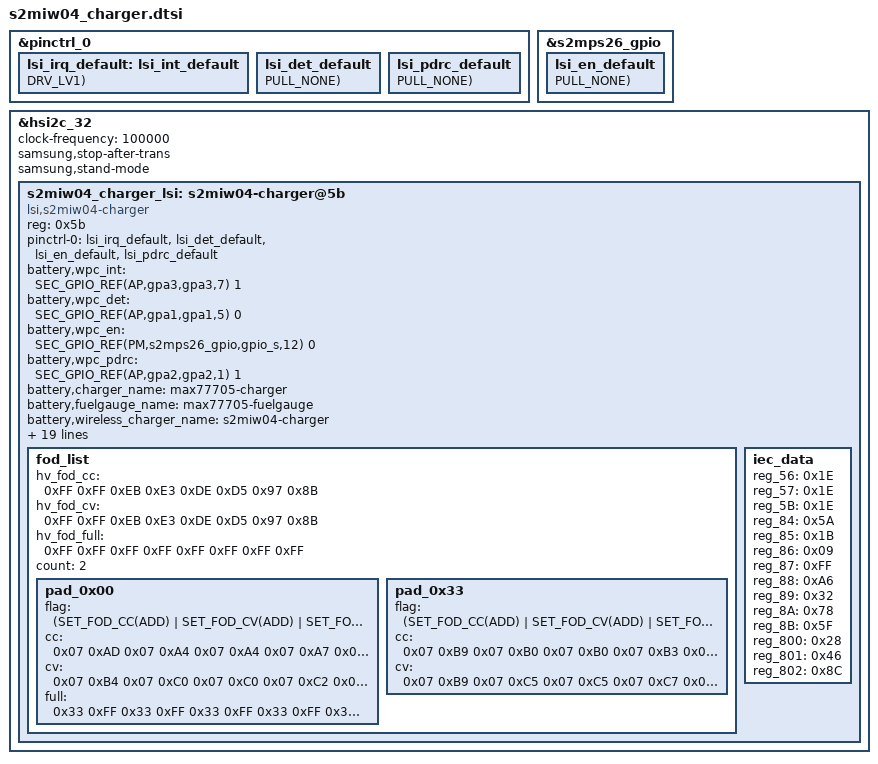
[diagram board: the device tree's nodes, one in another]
#include <dt-bindings/battery/sec-battery.h>

&pinctrl_0 {
	lsi_irq_default: lsi_int_default {
		GPIO_CONFIG_PUD_DRV(AP,gpa3,gpa3,7, FUNC_INPUT_WAKEUP, PULL_NONE, DRV_LV1);
	};
};

&pinctrl_0 {
	lsi_det_default: lsi_det_default {
		GPIO_CONFIG_PUD(AP,gpa1,gpa1,5, FUNC_INPUT_WAKEUP, PULL_NONE);
	};
};

&s2mps26_gpio {
	lsi_en_default: lsi_en_default {
		GPIO_CONFIG_PUD(PM,s2mps26_gpio,gpio_s,12, FUNC_OUTPUT_LOW, PULL_NONE);
	};
};

&hsi2c_32 {
	#address-cells = <1>;
	#size-cells = <0>;
	status = "okay";
	clock-frequency = <100000>;

	s2miw04_charger: s2miw04-charger@3b {
		compatible = "lsi,s2miw04-charger";
		reg = <0x3b>;
		status = "okay";

		pinctrl-names = "default";
		pinctrl-0 = <&lsi_irq_default &lsi_det_default &lsi_en_default>;

		battery,wpc_int = <SEC_GPIO_REF(AP,gpa3,gpa3,7) 1>; /* MFC_AP_INT */
		battery,wpc_det = <SEC_GPIO_REF(AP,gpa1,gpa1,5) 0>; /* WPC_DET */
#if 0
		battery,mst_pwr_en = <SEC_GPIO_REF(${lsi_pwr_en_gpio}) 0>; /* MST_PWR_EN */
#endif
		battery,wpc_en = <SEC_GPIO_REF(PM,s2mps26_gpio,gpio_s,12) 0>; /* WPC_EN */

		battery,charger_name = "max77705-charger";
		battery,fuelgauge_name = "max77705-fuelgauge";
		battery,wireless_charger_name = "s2miw04-charger";
		battery,wc_cover_rpp = <0x44>;
		battery,phone_fod_threshold = <0x3b>;
		battery,wireless20_vout_list = <WIRELESS_VOUT_11V /* 0xA0 */
						WIRELESS_VOUT_11V /* 0xA1 */
						WIRELESS_VOUT_11V /* 0xA2 */
						WIRELESS_VOUT_11V /* 0xA3 */
						WIRELESS_VOUT_11V /* 0xA4 */
						WIRELESS_VOUT_11V>; /* 0xA5 */
		battery,wireless20_vrect_list = <MFC_AFC_CONF_12V_TX
						MFC_AFC_CONF_12_5V_TX
						MFC_AFC_CONF_12_5V_TX
						MFC_AFC_CONF_12_5V_TX
						MFC_AFC_CONF_12_5V_TX
						MFC_AFC_CONF_12_5V_TX>;
		battery,wireless20_max_power_list = <SEC_WIRELESS_RX_POWER_12W
						SEC_WIRELESS_RX_POWER_15W
						SEC_WIRELESS_RX_POWER_15W
						SEC_WIRELESS_RX_POWER_15W
						SEC_WIRELESS_RX_POWER_15W
						SEC_WIRELESS_RX_POWER_15W>;
		battery,oc_fod1 = <1100>;

		fod_list {
			count = <1>;

			pad_0x00 { /* DEFAULT */
				flag = <(SET_FOD_CC(ADD) | SET_FOD_CV(USE_CC) | SET_FOD_FULL(ADD))>;
				cc = <0x06 0xAA 0x06 0xAA 0x06 0xAA 0x06 0x99 0x06 0x99
					0x06 0x99 0x0C 0x85 0x0C 0x85 0x08 0x9E 0x08 0x9E>;
				full = <0xFF 0xFF 0xFF 0xFF 0xFF 0xFF 0xFF 0xFF 0xFF 0xFF
					0xFF 0xFF 0xFF 0xFF 0xFF 0xFF 0xFF 0xFF 0xFF 0xFF>;
			};
		};
	};
};

/* /home/dpi/qb5_8815/workspace/P4_1716/android/kernel/kmodule/battery/stable/r11/wireless/s2miw04/s2miw04_charger.r11s.dtsi */
#include <dt-bindings/battery/sec-battery.h>

#if 1
&pinctrl_0 {
	lsi_pdrc_default: lsi_pdrc_default {
		GPIO_CONFIG_PUD(AP,gpa2,gpa2,1, FUNC_INPUT_WAKEUP, PULL_NONE);
	};
};
#endif

&hsi2c_32 {
	samsung,stop-after-trans;
	samsung,stand-mode;

	/delete-node/ s2miw04-charger@3b;

	s2miw04_charger_lsi: s2miw04-charger@5b {
		compatible = "lsi,s2miw04-charger";
		reg = <0x5b>;
		status = "okay";

		pinctrl-names = "default";
#if 1
		pinctrl-0 = <&lsi_irq_default &lsi_det_default &lsi_en_default &lsi_pdrc_default>;
#else
		pinctrl-0 = <&lsi_irq_default &lsi_det_default &lsi_en_default>;
#endif

		battery,wpc_int = <SEC_GPIO_REF(AP,gpa3,gpa3,7) 1>; /* MFC_AP_INT */
		battery,wpc_det = <SEC_GPIO_REF(AP,gpa1,gpa1,5) 0>; /* WPC_DET */
#if 0
		battery,mst_pwr_en = <SEC_GPIO_REF(${lsi_pwr_en_gpio}) 0>; /* MST_PWR_EN */
#endif
		battery,wpc_en = <SEC_GPIO_REF(PM,s2mps26_gpio,gpio_s,12) 0>; /* WPC_EN */
#if 1
		battery,wpc_pdrc = <SEC_GPIO_REF(AP,gpa2,gpa2,1) 1>; /* VRECT_INT */
#endif

		battery,charger_name = "max77705-charger";
		battery,fuelgauge_name = "max77705-fuelgauge";
		battery,wireless_charger_name = "s2miw04-charger";
		battery,wc_cover_rpp = <0x44>;
		battery,phone_fod_threshold = <0x3b>;
		battery,wireless20_vout_list = <WIRELESS_VOUT_9V /* 0xA0 */
						WIRELESS_VOUT_11V /* 0xA1 */
						WIRELESS_VOUT_11V /* 0xA2 */
						WIRELESS_VOUT_11V /* 0xA3 */
						WIRELESS_VOUT_11V /* 0xA4 */
						WIRELESS_VOUT_11V>; /* 0xA5 */
		battery,wireless20_vrect_list = <MFC_AFC_CONF_12V_TX
						MFC_AFC_CONF_12_5V_TX
						MFC_AFC_CONF_12_5V_TX
						MFC_AFC_CONF_12_5V_TX
						MFC_AFC_CONF_12_5V_TX
						MFC_AFC_CONF_12_5V_TX>;
		battery,wireless20_max_power_list = <SEC_WIRELESS_RX_POWER_12W
						SEC_WIRELESS_RX_POWER_15W
						SEC_WIRELESS_RX_POWER_15W
						SEC_WIRELESS_RX_POWER_15W
						SEC_WIRELESS_RX_POWER_15W
						SEC_WIRELESS_RX_POWER_15W>;
		battery,oc_fod1 = <1100>;
		battery,phone_fod_thresh1 = <0x0DAC>; /* 3500 */
		battery,buds_fod_thresh1 = <0x0DAC>; /* 3500 */
		battery,ping_freq = <1470>;
		battery,wpc_vout_ctrl_full = <WIRELESS_VOUT_5V_STEP>;
		battery,tx_gear_min_op_freq_delay = <4000>;
		battery,mis_align_guide;
		battery,mis_align_target_vout = <5000>;
		battery,unknown_cmb_ctrl;
		battery,default_clamp_volt;

		fod_list {
			hv_fod_cc = <0xFF 0xFF 0xEB 0xE3 0xDE 0xD5 0x97 0x8B>;
			hv_fod_cv = <0xFF 0xFF 0xEB 0xE3 0xDE 0xD5 0x97 0x8B>;
			hv_fod_full = <0xFF 0xFF 0xFF 0xFF 0xFF 0xFF 0xFF 0xFF>;

			count = <2>;
			pad_0x00 { /* DEFAULT */
				flag = <(SET_FOD_CC(ADD) | SET_FOD_CV(ADD) | SET_FOD_FULL(ADD))>;
				cc = <0x07 0xAD 0x07 0xA4 0x07 0xA4 0x07 0xA7 0x0E 0x89
					0x0E 0x89 0x0E 0x89 0x0E 0x89 0x13 0x75 0x13 0x75>;
				cv = <0x07 0xB4 0x07 0xC0 0x07 0xC0 0x07 0xC2 0x0E 0xA4
					0x0E 0xA4 0x0E 0xA4 0x0E 0xA4 0x13 0x90 0x13 0x90>;
				full = <0x33 0xFF 0x33 0xFF 0x33 0xFF 0x33 0xFF 0x33 0xFF
					0x33 0xFF 0x33 0xFF 0x33 0xFF 0x33 0xFF 0x33 0xFF>;
			};
			pad_0x33 { /* N5100 landscape mode */
				flag = <(SET_FOD_CC(ADD) | SET_FOD_CV(ADD) | SET_FOD_FULL(USE_DEFAULT))>;
				cc = <0x07 0xB9 0x07 0xB0 0x07 0xB0 0x07 0xB3 0x0E 0x95
					0x0E 0x95 0x0E 0x95 0x0E 0x95 0x13 0x81 0x13 0x81>;
				cv = <0x07 0xB9 0x07 0xC5 0x07 0xC5 0x07 0xC7 0x0E 0xA9
					0x0E 0xA9 0x0E 0xA9 0x0E 0xA9 0x13 0x95 0x13 0x95>;
			};
		};

		iec_data {
			reg_56 = <0x1E>;
			reg_57 = <0x1E>;
			reg_5B = <0x1E>;
			reg_84 = <0x5A>;
			reg_85 = <0x1B>;
			reg_86 = <0x09>;
			reg_87 = <0xFF>;
			reg_88 = <0xA6>;
			reg_89 = <0x32>;
			reg_8A = <0x78>;
			reg_8B = <0x5F>;
			reg_800 = <0x28>;
			reg_801 = <0x46>;
			reg_802 = <0x8C>;
		};
	};
};
